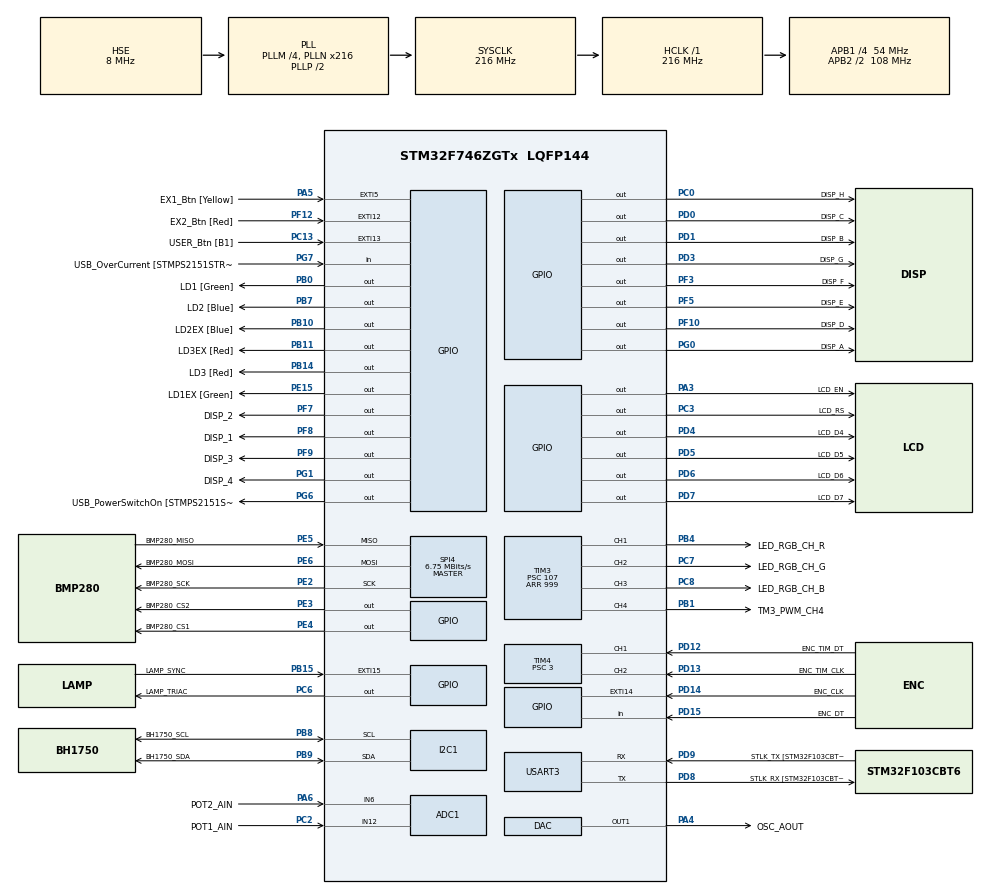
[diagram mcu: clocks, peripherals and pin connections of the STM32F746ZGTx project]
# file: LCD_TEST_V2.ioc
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ADC1.Channel-0\#ChannelRegularConversion=ADC_CHANNEL_12
ADC1.Channel-1\#ChannelRegularConversion=ADC_CHANNEL_6
ADC1.ClockPrescaler=ADC_CLOCK_SYNC_PCLK_DIV8
ADC1.ContinuousConvMode=DISABLE
ADC1.DMAContinuousRequests=ENABLE
ADC1.EOCSelection=ADC_EOC_SEQ_CONV
ADC1.InjNumberOfConversion=0
ADC1.NbrOfConversion=2
ADC1.NbrOfConversionFlag=1
ADC1.Rank-0\#ChannelRegularConversion=1
ADC1.Rank-1\#ChannelRegularConversion=2
ADC1.SamplingTime-0\#ChannelRegularConversion=ADC_SAMPLETIME_480CYCLES
ADC1.SamplingTime-1\#ChannelRegularConversion=ADC_SAMPLETIME_480CYCLES
ADC1.master=1
DAC.DAC_Trigger=DAC_TRIGGER_NONE
Dma.ADC1.0.Direction=DMA_PERIPH_TO_MEMORY
Dma.ADC1.0.FIFOMode=DMA_FIFOMODE_DISABLE
Dma.ADC1.0.Instance=DMA2_Stream0
Dma.ADC1.0.MemDataAlignment=DMA_MDATAALIGN_HALFWORD
Dma.ADC1.0.MemInc=DMA_MINC_ENABLE
Dma.ADC1.0.Mode=DMA_CIRCULAR
Dma.ADC1.0.PeriphDataAlignment=DMA_PDATAALIGN_HALFWORD
Dma.ADC1.0.PeriphInc=DMA_PINC_DISABLE
Dma.ADC1.0.Priority=DMA_PRIORITY_LOW
Dma.DAC1.1.Direction=DMA_MEMORY_TO_PERIPH
Dma.DAC1.1.FIFOMode=DMA_FIFOMODE_DISABLE
Dma.DAC1.1.Instance=DMA1_Stream5
Dma.DAC1.1.MemDataAlignment=DMA_MDATAALIGN_HALFWORD
Dma.DAC1.1.MemInc=DMA_MINC_ENABLE
Dma.DAC1.1.Mode=DMA_CIRCULAR
Dma.DAC1.1.PeriphDataAlignment=DMA_PDATAALIGN_HALFWORD
Dma.DAC1.1.PeriphInc=DMA_PINC_DISABLE
Dma.DAC1.1.Priority=DMA_PRIORITY_HIGH
Dma.Request0=ADC1
Dma.Request1=DAC1
I2C1.Timing=0x20404768
Mcu.Family=STM32F7
Mcu.Name=STM32F746ZGTx
Mcu.Package=LQFP144
NVIC.DMA1_Stream5_IRQn=true\:0\:0\:false\:false\:true\:false\:true
NVIC.DMA2_Stream0_IRQn=true\:0\:0\:false\:false\:true\:false\:true
NVIC.EXTI15_10_IRQn=true\:0\:0\:false\:false\:true\:true\:true
NVIC.EXTI9_5_IRQn=true\:0\:0\:false\:false\:true\:true\:true
NVIC.PriorityGroup=NVIC_PRIORITYGROUP_4
NVIC.TIM2_IRQn=true\:0\:0\:false\:false\:true\:true\:true
NVIC.TIM6_DAC_IRQn=true\:0\:0\:false\:false\:true\:true\:true
NVIC.TIM7_IRQn=true\:0\:0\:false\:false\:true\:true\:true
NVIC.USART3_IRQn=true\:0\:0\:false\:false\:true\:true\:true
PA1.GPIO_Label=RMII_REF_CLK [LAN8742A-CZ-TR_REFCLK0]
PA1.Signal=ETH_REF_CLK
PA10.GPIO_Label=USB_ID
PA10.Signal=USB_OTG_FS_ID
PA11.GPIO_Label=USB_DM
PA11.Signal=USB_OTG_FS_DM
PA12.GPIO_Label=USB_DP
PA12.Signal=USB_OTG_FS_DP
PA13.GPIO_Label=TMS
PA13.Mode=Serial_Wire
PA13.Signal=SYS_JTMS-SWDIO
PA14.GPIO_Label=TCK
PA14.Mode=Serial_Wire
PA14.Signal=SYS_JTCK-SWCLK
PA2.GPIO_Label=RMII_MDIO [LAN8742A-CZ-TR_MDIO]
PA2.Signal=ETH_MDIO
PA3.GPIO_Label=LCD_EN
PA3.Signal=GPIO_Output
PA4.GPIO_Label=OSC_AOUT
PA4.Signal=COMP_DAC1_group
PA5.GPIO_Label=EX1_Btn [Yellow]
PA5.GPIO_ModeDefaultEXTI=GPIO_MODE_IT_FALLING
PA5.Signal=GPXTI5
PA6.GPIO_Label=POT2_AIN
PA6.Signal=ADCx_IN6
PA8.GPIO_Label=USB_SOF [TP1]
PA8.Signal=USB_OTG_FS_SOF
PA9.GPIO_Label=USB_VBUS
PA9.Signal=USB_OTG_FS_VBUS
PB0.GPIO_Label=LD1 [Green]
PB0.Signal=GPIO_Output
PB1.GPIO_Label=TM3_PWM_CH4
PB1.Signal=S_TIM3_CH4
PB10.GPIO_Label=LD2EX [Blue]
PB10.Signal=GPIO_Output
PB11.GPIO_Label=LD3EX [Red]
PB11.Signal=GPIO_Output
PB13.GPIO_Label=RMII_TXD1 [LAN8742A-CZ-TR_TXD1]
PB13.Signal=ETH_TXD1
PB14.GPIO_Label=LD3 [Red]
PB14.Signal=GPIO_Output
PB15.GPIO_Label=LAMP_SYNC
PB15.Signal=GPXTI15
PB3.GPIO_Label=SW0
PB3.Signal=SYS_JTDO-SWO
PB4.GPIO_Label=LED_RGB_CH_R
PB4.Signal=S_TIM3_CH1
PB7.GPIO_Label=LD2 [Blue]
PB7.Signal=GPIO_Output
PB8.GPIO_Label=BH1750_SCL
PB8.Mode=I2C
PB8.Signal=I2C1_SCL
PB9.GPIO_Label=BH1750_SDA
PB9.Mode=I2C
PB9.Signal=I2C1_SDA
PC0.GPIO_Label=DISP_H
PC0.GPIO_ModeDefaultOutputPP=GPIO_MODE_OUTPUT_OD
PC0.GPIO_PuPd=GPIO_PULLUP
PC0.Signal=GPIO_Output
PC1.GPIO_Label=RMII_MDC [LAN8742A-CZ-TR_MDC]
PC1.Signal=ETH_MDC
PC13.GPIO_Label=USER_Btn [B1]
PC13.Signal=GPXTI13
PC14/OSC32_IN.Mode=LSE-External-Oscillator
PC14/OSC32_IN.Signal=RCC_OSC32_IN
PC15/OSC32_OUT.Mode=LSE-External-Oscillator
PC15/OSC32_OUT.Signal=RCC_OSC32_OUT
PC2.GPIO_Label=POT1_AIN
PC2.Signal=ADCx_IN12
PC3.GPIO_Label=LCD_RS
PC3.Signal=GPIO_Output
PC4.GPIO_Label=RMII_RXD0 [LAN8742A-CZ-TR_RXD0]
PC4.Signal=ETH_RXD0
PC5.GPIO_Label=RMII_RXD1 [LAN8742A-CZ-TR_RXD1]
PC5.Signal=ETH_RXD1
PC6.GPIO_Label=LAMP_TRIAC
PC6.GPIO_Speed=GPIO_SPEED_FREQ_HIGH
PC6.Signal=GPIO_Output
PC7.GPIO_Label=LED_RGB_CH_G
PC7.Signal=S_TIM3_CH2
PC8.GPIO_Label=LED_RGB_CH_B
PC8.Signal=S_TIM3_CH3
PD0.GPIO_Label=DISP_C
PD0.GPIO_ModeDefaultOutputPP=GPIO_MODE_OUTPUT_OD
PD0.GPIO_PuPd=GPIO_PULLUP
PD0.Signal=GPIO_Output
PD1.GPIO_Label=DISP_B
PD1.GPIO_ModeDefaultOutputPP=GPIO_MODE_OUTPUT_OD
PD1.GPIO_PuPd=GPIO_PULLUP
PD1.Signal=GPIO_Output
PD12.GPIO_Label=ENC_TIM_DT
PD12.Signal=S_TIM4_CH1
PD13.GPIO_Label=ENC_TIM_CLK
PD13.Signal=S_TIM4_CH2
PD14.GPIO_Label=ENC_CLK
PD14.GPIO_ModeDefaultEXTI=GPIO_MODE_IT_FALLING
PD14.Signal=GPXTI14
PD15.GPIO_Label=ENC_DT
PD15.Signal=GPIO_Input
PD3.GPIO_Label=DISP_G
PD3.GPIO_ModeDefaultOutputPP=GPIO_MODE_OUTPUT_OD
PD3.GPIO_PuPd=GPIO_PULLUP
PD3.Signal=GPIO_Output
PD4.GPIO_Label=LCD_D4
PD4.Signal=GPIO_Output
PD5.GPIO_Label=LCD_D5
PD5.Signal=GPIO_Output
PD6.GPIO_Label=LCD_D6
PD6.Signal=GPIO_Output
PD7.GPIO_Label=LCD_D7
PD7.Signal=GPIO_Output
PD8.GPIO_Label=STLK_RX [STM32F103CBT6_PA3]
PD8.Mode=Asynchronous
PD8.Signal=USART3_TX
PD9.GPIO_Label=STLK_TX [STM32F103CBT6_PA2]
PD9.Mode=Asynchronous
PD9.Signal=USART3_RX
PE15.GPIO_Label=LD1EX [Green]
PE15.Signal=GPIO_Output
PE2.GPIO_Label=BMP280_SCK
PE2.Mode=Full_Duplex_Master
PE2.Signal=SPI4_SCK
PE3.GPIO_Label=BMP280_CS2
PE3.GPIO_Speed=GPIO_SPEED_FREQ_VERY_HIGH
PE3.PinState=GPIO_PIN_SET
PE3.Signal=GPIO_Output
PE4.GPIO_Label=BMP280_CS1
PE4.GPIO_Speed=GPIO_SPEED_FREQ_VERY_HIGH
PE4.PinState=GPIO_PIN_SET
PE4.Signal=GPIO_Output
PE5.GPIO_Label=BMP280_MISO
PE5.Mode=Full_Duplex_Master
PE5.Signal=SPI4_MISO
PE6.GPIO_Label=BMP280_MOSI
PE6.Mode=Full_Duplex_Master
PE6.Signal=SPI4_MOSI
PF10.GPIO_Label=DISP_D
PF10.GPIO_ModeDefaultOutputPP=GPIO_MODE_OUTPUT_OD
PF10.GPIO_PuPd=GPIO_PULLUP
PF10.Signal=GPIO_Output
PF12.GPIO_Label=EX2_Btn [Red]
PF12.Signal=GPXTI12
PF3.GPIO_Label=DISP_F
PF3.GPIO_ModeDefaultOutputPP=GPIO_MODE_OUTPUT_OD
PF3.GPIO_PuPd=GPIO_PULLUP
PF3.Signal=GPIO_Output
PF5.GPIO_Label=DISP_E
PF5.GPIO_ModeDefaultOutputPP=GPIO_MODE_OUTPUT_OD
PF5.GPIO_PuPd=GPIO_PULLUP
PF5.Signal=GPIO_Output
PF7.GPIO_Label=DISP_2
PF7.Signal=GPIO_Output
PF8.GPIO_Label=DISP_1
PF8.Signal=GPIO_Output
PF9.GPIO_Label=DISP_3
PF9.Signal=GPIO_Output
PG0.GPIO_Label=DISP_A
PG0.GPIO_ModeDefaultOutputPP=GPIO_MODE_OUTPUT_OD
PG0.GPIO_PuPd=GPIO_PULLUP
PG0.Signal=GPIO_Output
PG1.GPIO_Label=DISP_4
PG1.Signal=GPIO_Output
PG11.GPIO_Label=RMII_TX_EN [LAN8742A-CZ-TR_TXEN]
PG11.Signal=ETH_TX_EN
PG13.GPIO_Label=RMII_TXD0 [LAN8742A-CZ-TR_TXD0]
PG13.Signal=ETH_TXD0
PG6.GPIO_Label=USB_PowerSwitchOn [STMPS2151STR_EN]
PG6.Signal=GPIO_Output
PG7.GPIO_Label=USB_OverCurrent [STMPS2151STR_FAULT]
PG7.Signal=GPIO_Input
PH0/OSC_IN.GPIO_Label=MCO [STM32F103CBT6_PA8]
PH0/OSC_IN.Mode=HSE-External-Clock-Source
PH0/OSC_IN.Signal=RCC_OSC_IN
PH1/OSC_OUT.Mode=HSE-External-Clock-Source
PH1/OSC_OUT.Signal=RCC_OSC_OUT
ProjectManager.HeapSize=0x200
ProjectManager.StackSize=0x400
ProjectManager.TargetToolchain=STM32CubeIDE
RCC.48MHZClocksFreq_Value=24000000
RCC.AHBFreq_Value=216000000
RCC.APB1CLKDivider=RCC_HCLK_DIV4
RCC.APB1Freq_Value=54000000
RCC.APB1TimFreq_Value=108000000
RCC.APB2CLKDivider=RCC_HCLK_DIV2
RCC.APB2Freq_Value=108000000
RCC.APB2TimFreq_Value=216000000
RCC.CortexFreq_Value=216000000
RCC.HCLKFreq_Value=216000000
RCC.HSE_VALUE=8000000
RCC.HSI_VALUE=16000000
RCC.PLLM=4
RCC.PLLMUL=RCC_PLL_MUL9
RCC.PLLN=216
RCC.PLLQ=3
RCC.PLLSourceVirtual=RCC_PLLSOURCE_HSE
RCC.PRESCALERUSB=RCC_USBCLKSOURCE_PLL_DIV1_5
RCC.SYSCLKFreq_VALUE=216000000
RCC.SYSCLKSource=RCC_SYSCLKSOURCE_PLLCLK
RCC.SYSCLKSourceVirtual=RCC_SYSCLKSOURCE_PLLCLK
RCC.USBFreq_Value=144000000
RCC.VCOOutputFreq_Value=432000000
SH.ADCx_IN12.0=ADC1_IN12,IN12
SH.ADCx_IN6.0=ADC1_IN6,IN6
SH.COMP_DAC1_group.0=DAC_OUT1,DAC_OUT1
SH.S_TIM3_CH1.0=TIM3_CH1,PWM Generation1 CH1
SH.S_TIM3_CH2.0=TIM3_CH2,PWM Generation2 CH2
SH.S_TIM3_CH3.0=TIM3_CH3,PWM Generation3 CH3
SH.S_TIM3_CH4.0=TIM3_CH4,PWM Generation4 CH4
SH.S_TIM4_CH1.0=TIM4_CH1,Encoder_Interface
SH.S_TIM4_CH2.0=TIM4_CH2,Encoder_Interface
SPI4.BaudRatePrescaler=SPI_BAUDRATEPRESCALER_16
SPI4.CLKPhase=SPI_PHASE_2EDGE
SPI4.CLKPolarity=SPI_POLARITY_HIGH
SPI4.CalculateBaudRate=6.75 MBits/s
SPI4.DataSize=SPI_DATASIZE_8BIT
SPI4.Direction=SPI_DIRECTION_2LINES
SPI4.Mode=SPI_MODE_MASTER
SPI4.VirtualType=VM_MASTER
TIM2.Period=65535
TIM2.Prescaler=107
TIM3.Channel-PWM\ Generation1\ CH1=TIM_CHANNEL_1
TIM3.Channel-PWM\ Generation2\ CH2=TIM_CHANNEL_2
TIM3.Channel-PWM\ Generation3\ CH3=TIM_CHANNEL_3
TIM3.Channel-PWM\ Generation4\ CH4=TIM_CHANNEL_4
TIM3.Period=999
TIM3.Prescaler=107
TIM3.Pulse-PWM\ Generation2\ CH2=0
TIM3.Pulse-PWM\ Generation3\ CH3=0
TIM4.EncoderMode=TIM_ENCODERMODE_TI12
TIM4.IC1Polarity=TIM_ICPOLARITY_FALLING
TIM4.IC2Polarity=TIM_ICPOLARITY_FALLING
TIM4.Period=100
TIM4.Prescaler=3
TIM6.Period=999
TIM6.Prescaler=107
TIM6.TIM_MasterOutputTrigger=TIM_TRGO_UPDATE
TIM7.Period=999
TIM7.Prescaler=107
USART3.VirtualMode-Asynchronous=VM_ASYNC
VP_TIM2_VS_ClockSourceINT.Mode=Internal
VP_TIM2_VS_OPM.Mode=OPM_bit
VP_TIM3_VS_ClockSourceINT.Mode=Internal
VP_TIM6_VS_ClockSourceINT.Mode=Enable_Timer
VP_TIM7_VS_ClockSourceINT.Mode=Enable_Timer
board=NUCLEO-F746ZG

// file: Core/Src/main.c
/* USER CODE BEGIN Header */
/**
  ******************************************************************************
  * @file           : main.c
  * @brief          : Main program body
  ******************************************************************************
  * @attention
  *
  * <h2><center>&copy; Copyright (c) 2021 STMicroelectronics.
  * All rights reserved.</center></h2>
  *
  * This software component is licensed by ST under BSD 3-Clause license,
  * the "License"; You may not use this file except in compliance with the
  * License. You may obtain a copy of the License at:
  *                        opensource.org/licenses/BSD-3-Clause
  *
  ******************************************************************************
  */
/* USER CODE END Header */
#include "main.h"
#include "adc.h"
#include "dac.h"
#include "dma.h"
#include "i2c.h"
#include "spi.h"
#include "tim.h"
#include "usart.h"
#include "gpio.h"

/* USER CODE BEGIN Includes */
#include "lcd.h"
#include "lcd_config.h"
/* USER CODE END Includes */

void SystemClock_Config(void);

int main(void)
{

  /* MCU Configuration--------------------------------------------------------*/

  /* Reset of all peripherals, Initializes the Flash interface and the Systick. */
  HAL_Init();

  /* Configure the system clock */
  SystemClock_Config();

  /* Initialize all configured peripherals */
  MX_GPIO_Init();
  MX_DMA_Init();
  MX_USART3_UART_Init();
  MX_TIM2_Init();
  MX_TIM3_Init();
  MX_TIM4_Init();
  MX_I2C1_Init();
  MX_SPI4_Init();
  MX_ADC1_Init();
  MX_DAC_Init();
  MX_TIM6_Init();
  MX_TIM7_Init();
  /* USER CODE BEGIN 2 */
  HAL_TIM_Base_Start(&htim2);
  LCD_Init(&hlcd1);
  LCD_SetCursor(&hlcd1, 0, 0);
  LCD_printStr(&hlcd1, "NIE DZIAłA!");
  /* USER CODE END 2 */

  /* Infinite loop */
  while (1)
  {

  }
}

void SystemClock_Config(void)
{
  RCC_OscInitTypeDef RCC_OscInitStruct = {0};
  RCC_ClkInitTypeDef RCC_ClkInitStruct = {0};
  RCC_PeriphCLKInitTypeDef PeriphClkInitStruct = {0};

  /** Configure LSE Drive Capability
  */
  HAL_PWR_EnableBkUpAccess();
  /** Configure the main internal regulator output voltage
  */
  __HAL_RCC_PWR_CLK_ENABLE();
  __HAL_PWR_VOLTAGESCALING_CONFIG(PWR_REGULATOR_VOLTAGE_SCALE1);
  /** Initializes the RCC Oscillators according to the specified parameters
  * in the RCC_OscInitTypeDef structure.
  */
  RCC_OscInitStruct.OscillatorType = RCC_OSCILLATORTYPE_HSE;
  RCC_OscInitStruct.HSEState = RCC_HSE_BYPASS;
  RCC_OscInitStruct.PLL.PLLState = RCC_PLL_ON;
  RCC_OscInitStruct.PLL.PLLSource = RCC_PLLSOURCE_HSE;
  RCC_OscInitStruct.PLL.PLLM = 4;
  RCC_OscInitStruct.PLL.PLLN = 216;
  RCC_OscInitStruct.PLL.PLLP = RCC_PLLP_DIV2;
  RCC_OscInitStruct.PLL.PLLQ = 3;
  if (HAL_RCC_OscConfig(&RCC_OscInitStruct) != HAL_OK)
  {
    Error_Handler();
  }
  /** Activate the Over-Drive mode
  */
  if (HAL_PWREx_EnableOverDrive() != HAL_OK)
  {
    Error_Handler();
  }
  /** Initializes the CPU, AHB and APB buses clocks
  */
  RCC_ClkInitStruct.ClockType = RCC_CLOCKTYPE_HCLK|RCC_CLOCKTYPE_SYSCLK
                              |RCC_CLOCKTYPE_PCLK1|RCC_CLOCKTYPE_PCLK2;
  RCC_ClkInitStruct.SYSCLKSource = RCC_SYSCLKSOURCE_PLLCLK;
  RCC_ClkInitStruct.AHBCLKDivider = RCC_SYSCLK_DIV1;
  RCC_ClkInitStruct.APB1CLKDivider = RCC_HCLK_DIV4;
  RCC_ClkInitStruct.APB2CLKDivider = RCC_HCLK_DIV2;

  if (HAL_RCC_ClockConfig(&RCC_ClkInitStruct, FLASH_LATENCY_7) != HAL_OK)
  {
    Error_Handler();
  }
  PeriphClkInitStruct.PeriphClockSelection = RCC_PERIPHCLK_USART3|RCC_PERIPHCLK_I2C1;
  PeriphClkInitStruct.Usart3ClockSelection = RCC_USART3CLKSOURCE_PCLK1;
  PeriphClkInitStruct.I2c1ClockSelection = RCC_I2C1CLKSOURCE_PCLK1;
  if (HAL_RCCEx_PeriphCLKConfig(&PeriphClkInitStruct) != HAL_OK)
  {
    Error_Handler();
  }
}

void Error_Handler(void)
{
  __disable_irq();
  while (1)
  {
  }
}

/************************ (C) COPYRIGHT STMicroelectronics *****END OF FILE****/
